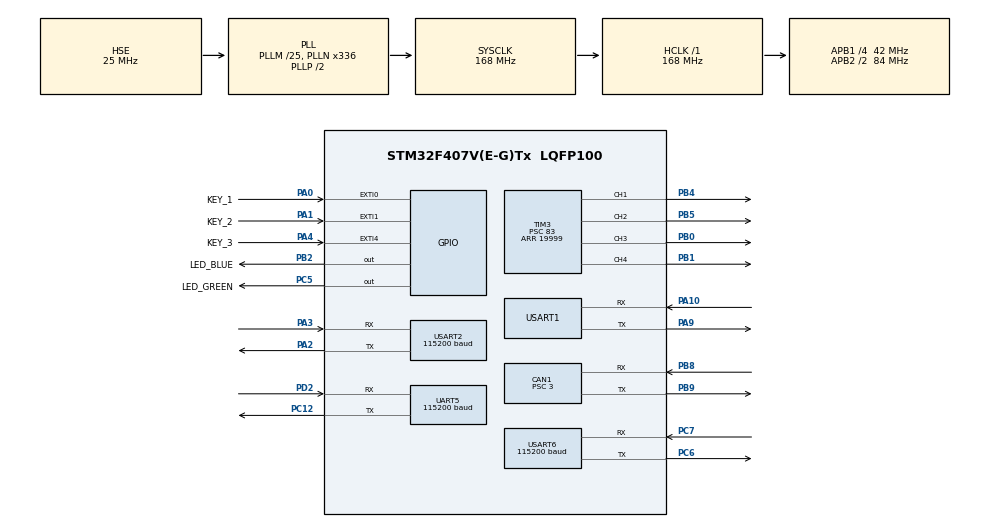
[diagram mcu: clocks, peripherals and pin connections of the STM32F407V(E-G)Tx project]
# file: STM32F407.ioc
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CAN1.BS1=CAN_BS1_11TQ
CAN1.BS2=CAN_BS2_2TQ
CAN1.CalculateBaudRate=1000000
CAN1.CalculateTimeBit=1000
CAN1.CalculateTimeQuantum=71.42857142857143
CAN1.Prescaler=3
Dma.Request0=USART2_RX
Dma.Request1=USART2_TX
Dma.Request2=UART5_RX
Dma.Request3=UART5_TX
Dma.Request4=USART6_RX
Dma.Request5=USART6_TX
Dma.UART5_RX.2.Direction=DMA_PERIPH_TO_MEMORY
Dma.UART5_RX.2.FIFOMode=DMA_FIFOMODE_DISABLE
Dma.UART5_RX.2.Instance=DMA1_Stream0
Dma.UART5_RX.2.MemDataAlignment=DMA_MDATAALIGN_BYTE
Dma.UART5_RX.2.MemInc=DMA_MINC_ENABLE
Dma.UART5_RX.2.Mode=DMA_CIRCULAR
Dma.UART5_RX.2.PeriphDataAlignment=DMA_PDATAALIGN_BYTE
Dma.UART5_RX.2.PeriphInc=DMA_PINC_DISABLE
Dma.UART5_RX.2.Priority=DMA_PRIORITY_HIGH
Dma.UART5_TX.3.Direction=DMA_MEMORY_TO_PERIPH
Dma.UART5_TX.3.FIFOMode=DMA_FIFOMODE_DISABLE
Dma.UART5_TX.3.Instance=DMA1_Stream7
Dma.UART5_TX.3.MemDataAlignment=DMA_MDATAALIGN_BYTE
Dma.UART5_TX.3.MemInc=DMA_MINC_ENABLE
Dma.UART5_TX.3.Mode=DMA_NORMAL
Dma.UART5_TX.3.PeriphDataAlignment=DMA_PDATAALIGN_BYTE
Dma.UART5_TX.3.PeriphInc=DMA_PINC_DISABLE
Dma.UART5_TX.3.Priority=DMA_PRIORITY_MEDIUM
Dma.USART2_RX.0.Direction=DMA_PERIPH_TO_MEMORY
Dma.USART2_RX.0.FIFOMode=DMA_FIFOMODE_DISABLE
Dma.USART2_RX.0.Instance=DMA1_Stream5
Dma.USART2_RX.0.MemDataAlignment=DMA_MDATAALIGN_BYTE
Dma.USART2_RX.0.MemInc=DMA_MINC_ENABLE
Dma.USART2_RX.0.Mode=DMA_CIRCULAR
Dma.USART2_RX.0.PeriphDataAlignment=DMA_PDATAALIGN_BYTE
Dma.USART2_RX.0.PeriphInc=DMA_PINC_DISABLE
Dma.USART2_RX.0.Priority=DMA_PRIORITY_HIGH
Dma.USART2_TX.1.Direction=DMA_MEMORY_TO_PERIPH
Dma.USART2_TX.1.FIFOMode=DMA_FIFOMODE_DISABLE
Dma.USART2_TX.1.Instance=DMA1_Stream6
Dma.USART2_TX.1.MemDataAlignment=DMA_MDATAALIGN_BYTE
Dma.USART2_TX.1.MemInc=DMA_MINC_ENABLE
Dma.USART2_TX.1.Mode=DMA_NORMAL
Dma.USART2_TX.1.PeriphDataAlignment=DMA_PDATAALIGN_BYTE
Dma.USART2_TX.1.PeriphInc=DMA_PINC_DISABLE
Dma.USART2_TX.1.Priority=DMA_PRIORITY_MEDIUM
Dma.USART6_RX.4.Direction=DMA_PERIPH_TO_MEMORY
Dma.USART6_RX.4.FIFOMode=DMA_FIFOMODE_DISABLE
Dma.USART6_RX.4.Instance=DMA2_Stream1
Dma.USART6_RX.4.MemDataAlignment=DMA_MDATAALIGN_BYTE
Dma.USART6_RX.4.MemInc=DMA_MINC_ENABLE
Dma.USART6_RX.4.Mode=DMA_CIRCULAR
Dma.USART6_RX.4.PeriphDataAlignment=DMA_PDATAALIGN_BYTE
Dma.USART6_RX.4.PeriphInc=DMA_PINC_DISABLE
Dma.USART6_RX.4.Priority=DMA_PRIORITY_HIGH
Dma.USART6_TX.5.Direction=DMA_MEMORY_TO_PERIPH
Dma.USART6_TX.5.FIFOMode=DMA_FIFOMODE_DISABLE
Dma.USART6_TX.5.Instance=DMA2_Stream6
Dma.USART6_TX.5.MemDataAlignment=DMA_MDATAALIGN_BYTE
Dma.USART6_TX.5.MemInc=DMA_MINC_ENABLE
Dma.USART6_TX.5.Mode=DMA_NORMAL
Dma.USART6_TX.5.PeriphDataAlignment=DMA_PDATAALIGN_BYTE
Dma.USART6_TX.5.PeriphInc=DMA_PINC_DISABLE
Dma.USART6_TX.5.Priority=DMA_PRIORITY_MEDIUM
Mcu.Family=STM32F4
Mcu.Name=STM32F407V(E-G)Tx
Mcu.Package=LQFP100
NVIC.CAN1_RX0_IRQn=true\:0\:0\:false\:false\:true\:true\:true\:true
NVIC.CAN1_SCE_IRQn=true\:0\:0\:false\:false\:true\:true\:true\:true
NVIC.DMA1_Stream0_IRQn=true\:5\:0\:false\:false\:true\:false\:true\:true
NVIC.DMA1_Stream5_IRQn=true\:5\:0\:false\:false\:true\:false\:true\:true
NVIC.DMA1_Stream6_IRQn=true\:5\:0\:false\:false\:true\:false\:true\:true
NVIC.DMA1_Stream7_IRQn=true\:5\:0\:false\:false\:true\:false\:true\:true
NVIC.DMA2_Stream1_IRQn=true\:5\:0\:false\:false\:true\:false\:true\:true
NVIC.DMA2_Stream6_IRQn=true\:5\:0\:false\:false\:true\:false\:true\:true
NVIC.EXTI0_IRQn=true\:0\:0\:false\:false\:true\:true\:true\:true
NVIC.EXTI1_IRQn=true\:0\:0\:false\:false\:true\:true\:true\:true
NVIC.EXTI4_IRQn=true\:0\:0\:false\:false\:true\:true\:true\:true
NVIC.PriorityGroup=NVIC_PRIORITYGROUP_4
NVIC.UART5_IRQn=true\:5\:0\:false\:false\:true\:true\:true\:true
NVIC.USART2_IRQn=true\:5\:0\:false\:false\:true\:true\:true\:true
NVIC.USART6_IRQn=true\:5\:0\:false\:false\:true\:true\:true\:true
PA0-WKUP.GPIO_Label=KEY_1
PA0-WKUP.GPIO_PuPd=GPIO_PULLDOWN
PA0-WKUP.Signal=GPXTI0
PA1.GPIO_Label=KEY_2
PA1.GPIO_ModeDefaultEXTI=GPIO_MODE_IT_FALLING
PA1.GPIO_PuPd=GPIO_PULLUP
PA1.Signal=GPXTI1
PA10.Mode=Asynchronous
PA10.Signal=USART1_RX
PA13.Mode=Serial_Wire
PA13.Signal=SYS_JTMS-SWDIO
PA14.Mode=Serial_Wire
PA14.Signal=SYS_JTCK-SWCLK
PA2.Mode=Asynchronous
PA2.Signal=USART2_TX
PA3.Mode=Asynchronous
PA3.Signal=USART2_RX
PA4.GPIO_Label=KEY_3
PA4.GPIO_ModeDefaultEXTI=GPIO_MODE_IT_FALLING
PA4.GPIO_PuPd=GPIO_PULLUP
PA4.Signal=GPXTI4
PA9.Mode=Asynchronous
PA9.Signal=USART1_TX
PB0.Signal=S_TIM3_CH3
PB1.Signal=S_TIM3_CH4
PB2.GPIO_Label=LED_BLUE
PB2.PinState=GPIO_PIN_SET
PB2.Signal=GPIO_Output
PB4.Signal=S_TIM3_CH1
PB5.Signal=S_TIM3_CH2
PB8.Mode=CAN_Activate
PB8.Signal=CAN1_RX
PB9.Mode=CAN_Activate
PB9.Signal=CAN1_TX
PC12.Mode=Asynchronous
PC12.Signal=UART5_TX
PC5.GPIO_Label=LED_GREEN
PC5.PinState=GPIO_PIN_SET
PC5.Signal=GPIO_Output
PC6.Mode=Asynchronous
PC6.Signal=USART6_TX
PC7.Mode=Asynchronous
PC7.Signal=USART6_RX
PD2.Mode=Asynchronous
PD2.Signal=UART5_RX
PH0-OSC_IN.Mode=HSE-External-Oscillator
PH0-OSC_IN.Signal=RCC_OSC_IN
PH1-OSC_OUT.Mode=HSE-External-Oscillator
PH1-OSC_OUT.Signal=RCC_OSC_OUT
ProjectManager.HeapSize=0x1000
ProjectManager.StackSize=0x1000
ProjectManager.TargetToolchain=CMake
RCC.48MHZClocksFreq_Value=48000000
RCC.AHBFreq_Value=168000000
RCC.APB1CLKDivider=RCC_HCLK_DIV4
RCC.APB1Freq_Value=42000000
RCC.APB1TimFreq_Value=84000000
RCC.APB2CLKDivider=RCC_HCLK_DIV2
RCC.APB2Freq_Value=84000000
RCC.APB2TimFreq_Value=168000000
RCC.CortexFreq_Value=168000000
RCC.HCLKFreq_Value=168000000
RCC.HSE_VALUE=25000000
RCC.HSI_VALUE=16000000
RCC.LSE_VALUE=32768
RCC.PLLM=25
RCC.PLLN=336
RCC.PLLQ=7
RCC.PLLSourceVirtual=RCC_PLLSOURCE_HSE
RCC.SYSCLKFreq_VALUE=168000000
RCC.SYSCLKSource=RCC_SYSCLKSOURCE_PLLCLK
RCC.VCOOutputFreq_Value=336000000
SH.S_TIM3_CH1.0=TIM3_CH1,PWM Generation1 CH1
SH.S_TIM3_CH2.0=TIM3_CH2,PWM Generation2 CH2
SH.S_TIM3_CH3.0=TIM3_CH3,PWM Generation3 CH3
SH.S_TIM3_CH4.0=TIM3_CH4,PWM Generation4 CH4
TIM3.Channel-PWM\ Generation1\ CH1=TIM_CHANNEL_1
TIM3.Channel-PWM\ Generation2\ CH2=TIM_CHANNEL_2
TIM3.Channel-PWM\ Generation3\ CH3=TIM_CHANNEL_3
TIM3.Channel-PWM\ Generation4\ CH4=TIM_CHANNEL_4
TIM3.Period=19999
TIM3.Prescaler=83
UART5.BaudRate=115200
UART5.VirtualMode=Asynchronous
USART1.VirtualMode=VM_ASYNC
USART2.BaudRate=115200
USART2.VirtualMode=VM_ASYNC
USART6.BaudRate=115200
USART6.VirtualMode=VM_ASYNC
VP_TIM3_VS_ClockSourceINT.Mode=Internal
board=custom

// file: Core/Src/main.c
/* USER CODE BEGIN Header */
/**
  ******************************************************************************
  * @file           : main.c
  * @brief          : Main program body
  ******************************************************************************
  * @attention
  *
  * Copyright (c) 2026 STMicroelectronics.
  * All rights reserved.
  *
  * This software is licensed under terms that can be found in the LICENSE file
  * in the root directory of this software component.
  * If no LICENSE file comes with this software, it is provided AS-IS.
  *
  ******************************************************************************
  */
/* USER CODE END Header */
#include "main.h"
#include "can.h"
#include "dma.h"
#include "tim.h"
#include "usart.h"
#include "gpio.h"

/* USER CODE BEGIN Includes */
#include "inspection_app.h"
/* USER CODE END Includes */

void SystemClock_Config(void);

int main(void)
{

  /* MCU Configuration--------------------------------------------------------*/

  /* Reset of all peripherals, Initializes the Flash interface and the Systick. */
  HAL_Init();

  /* Configure the system clock */
  SystemClock_Config();

  /* Initialize all configured peripherals */
  MX_GPIO_Init();
  MX_DMA_Init();
  MX_USART1_UART_Init();
  MX_CAN1_Init();
  MX_TIM3_Init();
  MX_USART2_UART_Init();
  MX_UART5_Init();
  MX_USART6_UART_Init();
  /* USER CODE BEGIN 2 */
  /* 初始化自写通讯程序；完成接线与机械标定前，舵机 PWM 保持关闭。 */
  Inspection_Init();
  /* USER CODE END 2 */

  /* Infinite loop */
  while (1)
  {

    /* USER CODE BEGIN 3 */
    /* 持续处理通讯和运动计算预览；当前不执行电机速度或舵机输出。 */
    Inspection_Poll();
  }
  /* USER CODE END 3 */
}

void SystemClock_Config(void)
{
  RCC_OscInitTypeDef RCC_OscInitStruct = {0};
  RCC_ClkInitTypeDef RCC_ClkInitStruct = {0};

  /** Configure the main internal regulator output voltage
  */
  __HAL_RCC_PWR_CLK_ENABLE();
  __HAL_PWR_VOLTAGESCALING_CONFIG(PWR_REGULATOR_VOLTAGE_SCALE1);

  /** Initializes the RCC Oscillators according to the specified parameters
  * in the RCC_OscInitTypeDef structure.
  */
  RCC_OscInitStruct.OscillatorType = RCC_OSCILLATORTYPE_HSE;
  RCC_OscInitStruct.HSEState = RCC_HSE_ON;
  RCC_OscInitStruct.PLL.PLLState = RCC_PLL_ON;
  RCC_OscInitStruct.PLL.PLLSource = RCC_PLLSOURCE_HSE;
  RCC_OscInitStruct.PLL.PLLM = 25;
  RCC_OscInitStruct.PLL.PLLN = 336;
  RCC_OscInitStruct.PLL.PLLP = RCC_PLLP_DIV2;
  RCC_OscInitStruct.PLL.PLLQ = 7;
  if (HAL_RCC_OscConfig(&RCC_OscInitStruct) != HAL_OK)
  {
    Error_Handler();
  }

  /** Initializes the CPU, AHB and APB buses clocks
  */
  RCC_ClkInitStruct.ClockType = RCC_CLOCKTYPE_HCLK|RCC_CLOCKTYPE_SYSCLK
                              |RCC_CLOCKTYPE_PCLK1|RCC_CLOCKTYPE_PCLK2;
  RCC_ClkInitStruct.SYSCLKSource = RCC_SYSCLKSOURCE_PLLCLK;
  RCC_ClkInitStruct.AHBCLKDivider = RCC_SYSCLK_DIV1;
  RCC_ClkInitStruct.APB1CLKDivider = RCC_HCLK_DIV4;
  RCC_ClkInitStruct.APB2CLKDivider = RCC_HCLK_DIV2;

  if (HAL_RCC_ClockConfig(&RCC_ClkInitStruct, FLASH_LATENCY_5) != HAL_OK)
  {
    Error_Handler();
  }
}

void Error_Handler(void)
{
  __disable_irq();
  while (1)
  {
  }
}
